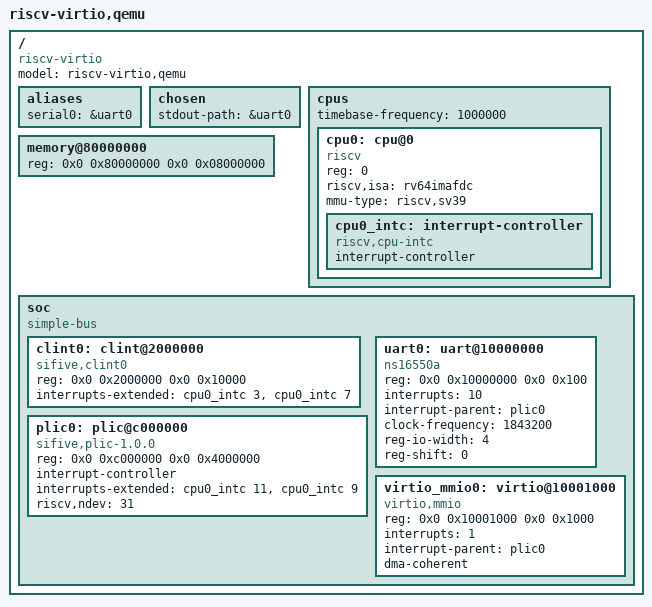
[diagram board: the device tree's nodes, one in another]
/dts-v1/;

/ {
	#address-cells = <2>;
	#size-cells = <2>;
	compatible = "riscv-virtio";
	model = "riscv-virtio,qemu";

	aliases {
		serial0 = &uart0;
	};

	chosen {
		stdout-path = &uart0;
	};

	cpus {
		#address-cells = <1>;
		#size-cells = <0>;
		timebase-frequency = <1000000>;

		cpu0: cpu@0 {
			device_type = "cpu";
			reg = <0>;
			status = "okay";
			compatible = "riscv";
			riscv,isa = "rv64imafdc";
			mmu-type = "riscv,sv39";

			cpu0_intc: interrupt-controller {
				#interrupt-cells = <1>;
				interrupt-controller;
				compatible = "riscv,cpu-intc";
			};
		};
	};

	memory@80000000 {
		device_type = "memory";
		reg = <0x0 0x80000000 0x0 0x08000000>;  /* 128 MiB */
	};

	soc {
		#address-cells = <2>;
		#size-cells = <2>;
		compatible = "simple-bus";
		ranges;

		clint0: clint@2000000 {
			compatible = "sifive,clint0", "riscv,clint0";
			reg = <0x0 0x2000000 0x0 0x10000>;
			interrupts-extended = <&cpu0_intc 3 &cpu0_intc 7>;
		};

		plic0: plic@c000000 {
			compatible = "sifive,plic-1.0.0";
			reg = <0x0 0xc000000 0x0 0x4000000>;
			#address-cells = <0>;
			#interrupt-cells = <1>;
			interrupt-controller;
			interrupts-extended = <&cpu0_intc 11 &cpu0_intc 9>;
			riscv,ndev = <31>;
		};

		uart0: uart@10000000 {
			compatible = "ns16550a";
			reg = <0x0 0x10000000 0x0 0x100>;
			interrupts = <10>;
			interrupt-parent = <&plic0>;
			clock-frequency = <1843200>;
			reg-io-width = <4>;
			reg-shift = <0>;
		};

		virtio_mmio0: virtio@10001000 {
			compatible = "virtio,mmio";
			reg = <0x0 0x10001000 0x0 0x1000>;
			interrupts = <1>;
			interrupt-parent = <&plic0>;
			dma-coherent;
		};
	};
};
